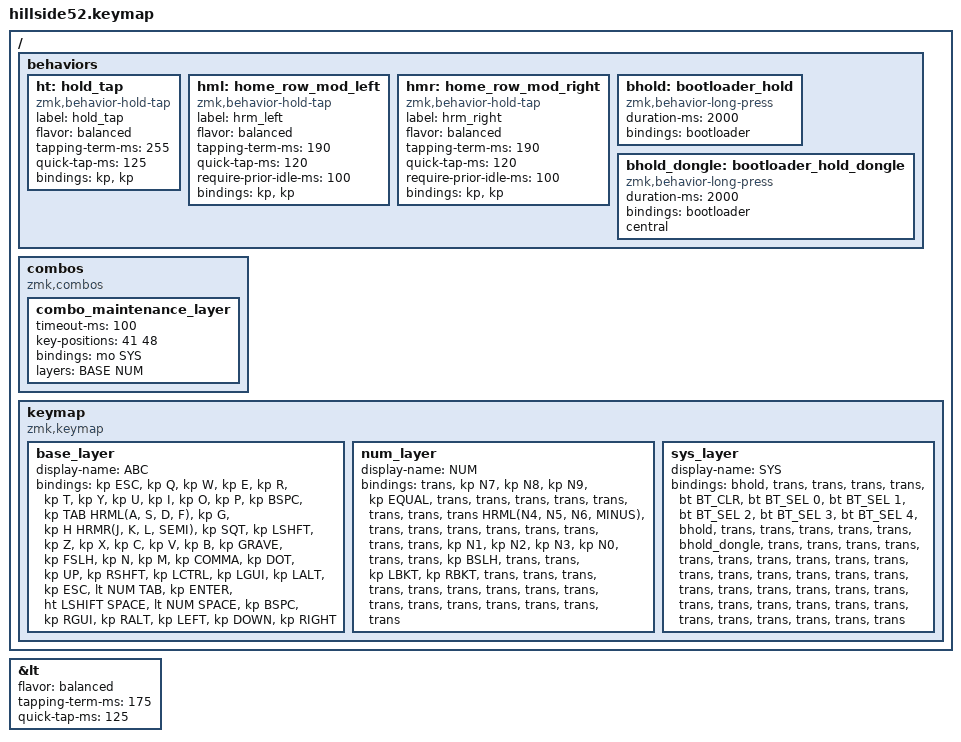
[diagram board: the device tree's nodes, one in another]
/*
 * Copyright (c) 2021-2022 The ZMK Contributors
 *
 * SPDX-License-Identifier: MIT
 */

#include <behaviors.dtsi>
#include <dt-bindings/zmk/keys.h>
#include <dt-bindings/zmk/bt.h>

#define BASE 0
#define NUM  1
#define SYS  2

/* Home row mods (tap = key, hold = mod). The dedicated modifier keys on the
 * base layer are the PRIMARY way to use mods; these home-row holds are an
 * optional second way. Behavior matches the forager / sweep / totemist setup
 * (balanced flavor, 190ms tapping-term, prior-idle guard, and deliberately
 * NO cross-hand positional gating -- see the note on hml below). */
#define HRML(k1,k2,k3,k4) &hml LSHIFT k1 &hml LCTRL k2 &hml LALT k3 &hml LGUI k4
#define HRMR(k1,k2,k3,k4) &hmr RGUI k1  &hmr RALT k2  &hmr RCTRL k3 &hmr RSHIFT k4

/* Positional hold-tap key positions, indexed into the matrix transform in
 * boards/shields/hillside52/hillside52.dtsi (0-based, in binding order).
 * Kept for reference; currently unused (see the note on hml below). */
#define KEYS_L 0 1 2 3 4 5 12 13 14 15 16 17 24 25 26 27 28 29 30 38 39 40   // left-hand keys
#define KEYS_R 6 7 8 9 10 11 18 19 20 21 22 23 31 32 33 34 35 36 37 49 50 51 // right-hand keys
#define THUMBS 41 42 43 44 45 46 47 48                                       // thumb keys

/* Layer-tap, used by the thumb keys `&lt NUM TAB` and `&lt NUM SPACE`.
 *
 * ZMK's stock `&lt` is `tap-preferred`, which only resolves a hold when the
 * tapping term expires -- pressing and releasing another key while it is held
 * does NOT trigger the hold. So a quick layer chord (hold the thumb, tap a
 * key, release) completed inside 200ms emits SPACE plus that key instead of
 * the layer keycode. `balanced` resolves the hold as soon as another key is
 * pressed and released, which is exactly what a layer chord looks like. */
&lt {
        flavor = "balanced";
        tapping-term-ms = <175>;
        quick-tap-ms = <125>;
};

/ {
        behaviors {
                // Thumb hold-tap (tap = TAB, hold = SHIFT). Timeless flavor,
                // no positional/idle guard so it works with either hand.
                ht: hold_tap {
                        label = "hold_tap";
                        compatible = "zmk,behavior-hold-tap";
                        #binding-cells = <2>;
                        flavor = "balanced";
                        tapping-term-ms = <255>;
                        quick-tap-ms = <125>;
                        bindings = <&kp>, <&kp>;
                };

                /* Homerow mods.
                 *
                 * NOTE: no `hold-trigger-key-positions` /
                 * `hold-trigger-on-release`. Those implement urob's cross-hand
                 * ("timeless") positional hold-tap, where a homerow mod can
                 * ONLY resolve as a hold if the next key is on the opposite
                 * half. That gate is absolute -- there is no timeout escape
                 * hatch -- so holding LGUI (F) and pressing C, both left hand,
                 * can never become a hold and just emits "fc". That breaks the
                 * whole left-hand shortcut cluster (CMD/CTRL + Q W A S Z X C V)
                 * and every left-hand capital via LSHIFT on A.
                 *
                 * With the gate removed, `require-prior-idle-ms` is the main
                 * guard against false mods mid-word, and the tapping term is
                 * the window in which a same-hand roll could still resolve as
                 * a hold (balanced resolves on the other key's release). 190ms
                 * with a 100ms prior-idle (was 220/150) biases toward HOLD,
                 * since missed holds proved far more common than false ones.
                 *
                 * Trade-off: a fast same-hand roll starting on the homerow
                 * after >100ms idle ("as", "sad") can register a mod. To go
                 * back, re-add the two properties (KEYS_R THUMBS for hml,
                 * KEYS_L THUMBS for hmr). Note this board also has dedicated
                 * modifier keys on the outer/bottom row, so the homerow holds
                 * are the secondary way to reach mods here either way. */
                hml: home_row_mod_left {
                        label = "hrm_left";
                        compatible = "zmk,behavior-hold-tap";
                        #binding-cells = <2>;
                        flavor = "balanced";
                        tapping-term-ms = <190>;
                        quick-tap-ms = <120>;
                        require-prior-idle-ms = <100>;
                        bindings = <&kp>, <&kp>;
                };

                hmr: home_row_mod_right {
                        label = "hrm_right";
                        compatible = "zmk,behavior-hold-tap";
                        #binding-cells = <2>;
                        flavor = "balanced";
                        tapping-term-ms = <190>;
                        quick-tap-ms = <120>;
                        require-prior-idle-ms = <100>;
                        bindings = <&kp>, <&kp>;
                };

                bhold: bootloader_hold {
                        compatible = "zmk,behavior-long-press";
                        #binding-cells = <0>;
                        duration-ms = <2000>;
                        bindings = <&bootloader>;
                };

                // Same 2s hold, retargeted at the split central via `central`. In
                // dongle mode that is the keyless USB dongle, which otherwise can
                // only reach its UF2 bootloader by opening its case. Standalone, the
                // central is the left half, so this just duplicates the left hold.
                bhold_dongle: bootloader_hold_dongle {
                        compatible = "zmk,behavior-long-press";
                        #binding-cells = <0>;
                        duration-ms = <2000>;
                        bindings = <&bootloader>;
                        central;
                };
        };

        combos {
                compatible = "zmk,combos";
                combo_maintenance_layer {
                        timeout-ms = <100>;
                        key-positions = <41 48>;
                        bindings = <&mo SYS>;
                        layers = <BASE NUM>;
                };
        };

        keymap {
                compatible = "zmk,keymap";

                base_layer {
                        display-name = "ABC";
                        bindings = <
&kp ESC      &kp Q        &kp W        &kp E        &kp R        &kp T                                                                                &kp Y        &kp U        &kp I        &kp O        &kp P        &kp BSPC
&kp TAB     HRML(A,           S,           D,           F)       &kp G                                                                                &kp H       HRMR(J,           K,           L,           SEMI)    &kp SQT
&kp LSHFT    &kp Z        &kp X        &kp C        &kp V        &kp B          &kp GRAVE                                                &kp FSLH     &kp N        &kp M        &kp COMMA    &kp DOT      &kp UP       &kp RSHFT
&kp LCTRL    &kp LGUI     &kp LALT                  &kp ESC      &lt NUM TAB    &kp ENTER    &ht LSHIFT SPACE           &lt NUM SPACE    &kp BSPC     &kp RGUI     &kp RALT                  &kp LEFT     &kp DOWN     &kp RIGHT
                        >;
                };

                num_layer {
                        display-name = "NUM";
                        bindings = <
&trans      &kp N7        &kp N8       &kp N9      &kp EQUAL     &trans                                                                               &trans         &trans         &trans        &trans        &trans        &trans
&trans     HRML(N4,           N5,          N6,         MINUS)    &trans                                                                               &trans         &trans         &trans        &trans        &trans        &trans
&trans      &kp N1        &kp N2       &kp N3      &kp N0        &trans          &trans                                                  &kp BSLH     &trans         &trans         &kp LBKT      &kp RBKT      &trans        &trans
&trans      &trans        &trans                   &trans        &trans          &trans      &trans                      &trans          &trans       &trans         &trans                       &trans        &trans        &trans
                        >;
                };

                sys_layer {
                        display-name = "SYS";
                        bindings = <
&bhold      &trans        &trans       &trans       &trans        &bt BT_CLR                                                                           &bt BT_SEL 0   &bt BT_SEL 1   &bt BT_SEL 2  &bt BT_SEL 3  &bt BT_SEL 4  &bhold
&trans      &trans        &trans       &trans       &trans        &bhold_dongle                                                                        &trans         &trans         &trans        &trans        &trans        &trans
&trans      &trans        &trans       &trans       &trans        &trans          &trans                                                  &trans       &trans         &trans         &trans         &trans        &trans        &trans
&trans      &trans        &trans                    &trans        &trans          &trans      &trans                      &trans          &trans       &trans         &trans                       &trans        &trans        &trans
                        >;
                };
        };
};
